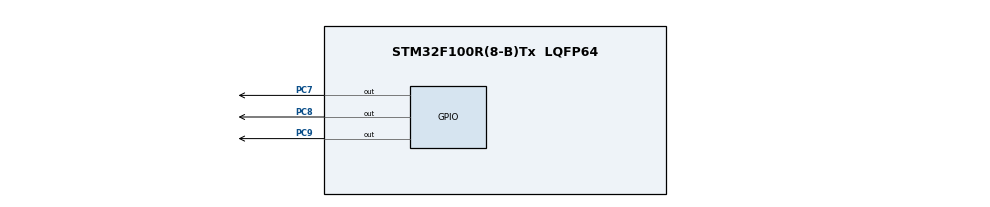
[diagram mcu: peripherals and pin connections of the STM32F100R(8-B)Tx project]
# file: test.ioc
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Mcu.Family=STM32F1
Mcu.Name=STM32F100R(8-B)Tx
Mcu.Package=LQFP64
NVIC.PriorityGroup=NVIC_PRIORITYGROUP_4
PA13.Mode=Serial_Wire
PA13.Signal=SYS_JTMS-SWDIO
PA14.Mode=Serial_Wire
PA14.Signal=SYS_JTCK-SWCLK
PC7.Signal=GPIO_Output
PC8.Signal=GPIO_Output
PC9.Signal=GPIO_Output
PD0-OSC_IN.Mode=HSE-External-Oscillator
PD0-OSC_IN.Signal=RCC_OSC_IN
PD1-OSC_OUT.Mode=HSE-External-Oscillator
PD1-OSC_OUT.Signal=RCC_OSC_OUT
ProjectManager.HeapSize=0x200
ProjectManager.StackSize=0x400
ProjectManager.TargetToolchain=EWARM V8.32
RCC.APB1Freq_Value=8000000
RCC.APB2Freq_Value=8000000
board=custom

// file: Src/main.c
/* USER CODE BEGIN Header */
/**
  ******************************************************************************
  * @file           : main.c
  * @brief          : Main program body
  ******************************************************************************
  * @attention
  *
  * <h2><center>&copy; Copyright (c) 2020 STMicroelectronics.
  * All rights reserved.</center></h2>
  *
  * This software component is licensed by ST under BSD 3-Clause license,
  * the "License"; You may not use this file except in compliance with the
  * License. You may obtain a copy of the License at:
  *                        opensource.org/licenses/BSD-3-Clause
  *
  ******************************************************************************
  */
/* USER CODE END Header */

#include "main.h"

/* USER CODE BEGIN PM */
#define GREEN_ON HAL_GPIO_WritePin(GPIOC, GPIO_PIN_8, GPIO_PIN_SET)
#define GREEN_OFF HAL_GPIO_WritePin(GPIOC, GPIO_PIN_8, GPIO_PIN_RESET)
#define YELLOW_ON HAL_GPIO_WritePin(GPIOC, GPIO_PIN_9, GPIO_PIN_SET)
#define YELLOW_OFF HAL_GPIO_WritePin(GPIOC, GPIO_PIN_9, GPIO_PIN_RESET)
#define RED_ON HAL_GPIO_WritePin(GPIOC, GPIO_PIN_10, GPIO_PIN_SET)
#define RED_OFF HAL_GPIO_WritePin(GPIOC, GPIO_PIN_10, GPIO_PIN_RESET)

/* USER CODE END PM */

void SystemClock_Config(void);
static void MX_GPIO_Init(void);

int main(void)
{

  /* MCU Configuration--------------------------------------------------------*/

  /* Reset of all peripherals, Initializes the Flash interface and the Systick. */
  HAL_Init();

  /* Configure the system clock */
  SystemClock_Config();

  /* Initialize all configured peripherals */
  MX_GPIO_Init();

  /* Infinite loop */
  /* USER CODE BEGIN WHILE */
  while (1)
  {

GREEN_ON;
HAL_Delay(5000);

GREEN_OFF;
HAL_Delay(500);
GREEN_ON;
HAL_Delay(500);
GREEN_OFF;
HAL_Delay(500);
GREEN_ON;
HAL_Delay(500);
GREEN_OFF;
HAL_Delay(500);
GREEN_ON;
HAL_Delay(500);
GREEN_OFF;
HAL_Delay(500);

YELLOW_ON;
HAL_Delay(3000);
YELLOW_OFF;

RED_ON;
HAL_Delay(5000);

YELLOW_ON;
HAL_Delay(2000);
YELLOW_OFF;
RED_OFF;

    /* USER CODE END WHILE */

  }
}

void SystemClock_Config(void)
{
  RCC_OscInitTypeDef RCC_OscInitStruct = {0};
  RCC_ClkInitTypeDef RCC_ClkInitStruct = {0};

  /** Initializes the CPU, AHB and APB busses clocks
  */
  RCC_OscInitStruct.OscillatorType = RCC_OSCILLATORTYPE_HSI;
  RCC_OscInitStruct.HSIState = RCC_HSI_ON;
  RCC_OscInitStruct.HSICalibrationValue = RCC_HSICALIBRATION_DEFAULT;
  RCC_OscInitStruct.PLL.PLLState = RCC_PLL_NONE;
  if (HAL_RCC_OscConfig(&RCC_OscInitStruct) != HAL_OK)
  {
    Error_Handler();
  }
  /** Initializes the CPU, AHB and APB busses clocks
  */
  RCC_ClkInitStruct.ClockType = RCC_CLOCKTYPE_HCLK|RCC_CLOCKTYPE_SYSCLK
                              |RCC_CLOCKTYPE_PCLK1|RCC_CLOCKTYPE_PCLK2;
  RCC_ClkInitStruct.SYSCLKSource = RCC_SYSCLKSOURCE_HSI;
  RCC_ClkInitStruct.AHBCLKDivider = RCC_SYSCLK_DIV1;
  RCC_ClkInitStruct.APB1CLKDivider = RCC_HCLK_DIV1;
  RCC_ClkInitStruct.APB2CLKDivider = RCC_HCLK_DIV1;

  if (HAL_RCC_ClockConfig(&RCC_ClkInitStruct, FLASH_LATENCY_0) != HAL_OK)
  {
    Error_Handler();
  }
}

static void MX_GPIO_Init(void)
{
  GPIO_InitTypeDef GPIO_InitStruct = {0};

  /* GPIO Ports Clock Enable */
  __HAL_RCC_GPIOD_CLK_ENABLE();
  __HAL_RCC_GPIOC_CLK_ENABLE();
  __HAL_RCC_GPIOA_CLK_ENABLE();

  /*Configure GPIO pin Output Level */
  HAL_GPIO_WritePin(GPIOC, GPIO_PIN_7|GPIO_PIN_8|GPIO_PIN_9, GPIO_PIN_RESET);

  /*Configure GPIO pins : PC7 PC8 PC9 */
  GPIO_InitStruct.Pin = GPIO_PIN_7|GPIO_PIN_8|GPIO_PIN_9;
  GPIO_InitStruct.Mode = GPIO_MODE_OUTPUT_PP;
  GPIO_InitStruct.Pull = GPIO_NOPULL;
  GPIO_InitStruct.Speed = GPIO_SPEED_FREQ_LOW;
  HAL_GPIO_Init(GPIOC, &GPIO_InitStruct);

}

void Error_Handler(void)
{
}

/************************ (C) COPYRIGHT STMicroelectronics *****END OF FILE****/
